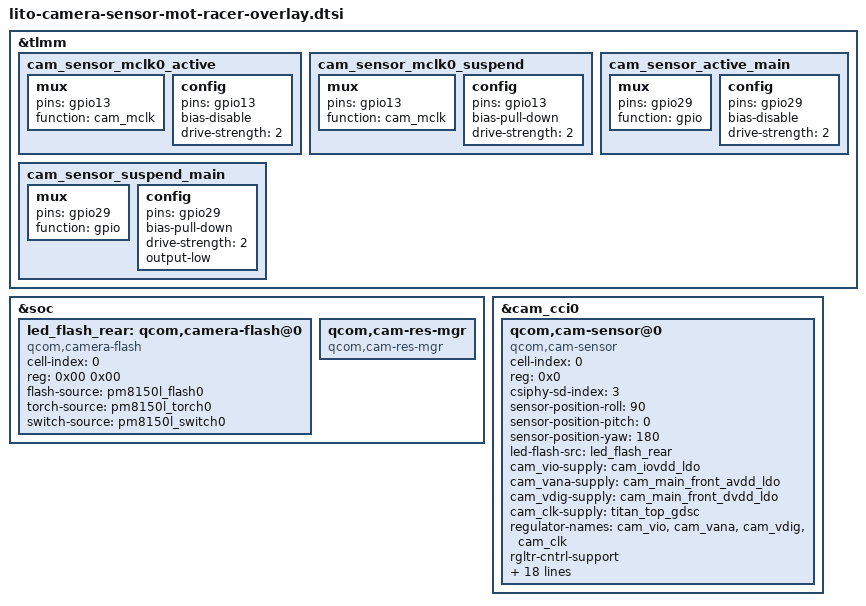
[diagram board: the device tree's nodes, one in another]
#include <dt-bindings/clock/qcom,camcc-lito.h>

&tlmm {
	cam_sensor_mclk0_active: cam_sensor_mclk0_active {
		/* MCLK0 */
		mux {
			pins = "gpio13";
			function = "cam_mclk";
		};

		config {
			pins = "gpio13";
			bias-disable; /* No PULL */
			drive-strength = <2>; /* 2 MA */
		};
	};

	cam_sensor_mclk0_suspend: cam_sensor_mclk0_suspend {
		/* MCLK0 */
		mux {
			pins = "gpio13";
			function = "cam_mclk";
		};

		config {
			pins = "gpio13";
			bias-pull-down; /* PULL DOWN */
			drive-strength = <2>; /* 2 MA */
		};
	};

	cam_sensor_active_main: cam_sensor_active_main {
		/* RESET */
		mux {
			pins = "gpio29";
			function = "gpio";
		};

		config {
			pins = "gpio29";
			bias-disable; /* No PULL */
			drive-strength = <2>; /* 2 MA */
		};
	};

	cam_sensor_suspend_main: cam_sensor_suspend_main {
		/* RESET */
		mux {
			pins = "gpio29";
			function = "gpio";
		};

		config {
			pins = "gpio29";
			bias-pull-down; /* PULL DOWN */
			drive-strength = <2>; /* 2 MA */
			output-low;
		};
	};
};

&soc {
	led_flash_rear: qcom,camera-flash@0 {
		cell-index = <0>;
		reg = <0x00 0x00>;
		compatible = "qcom,camera-flash";
		flash-source = <&pm8150l_flash0>;
		torch-source = <&pm8150l_torch0>;
		switch-source = <&pm8150l_switch0>;
	};

	qcom,cam-res-mgr {
		compatible = "qcom,cam-res-mgr";
		status = "ok";
	};
};

&cam_cci0 {
	qcom,cam-sensor@0 {
		cell-index = <0>;
		compatible = "qcom,cam-sensor";
		reg = <0x0>;
		csiphy-sd-index = <3>;
		sensor-position-roll = <90>;
		sensor-position-pitch = <0>;
		sensor-position-yaw = <180>;
		led-flash-src = <&led_flash_rear>;
		cam_vio-supply = <&cam_iovdd_ldo>;
		cam_vana-supply = <&cam_main_front_avdd_ldo>;
		cam_vdig-supply = <&cam_main_front_dvdd_ldo>;
		cam_clk-supply = <&titan_top_gdsc>;
		regulator-names = "cam_vio", "cam_vana", "cam_vdig",
			"cam_clk";
		rgltr-cntrl-support;
		rgltr-min-voltage = <1800000 2800000 1050000 0>;
		rgltr-max-voltage = <1800000 2800000 1050000 0>;
		rgltr-load-current = <0 80000 105000 0>;
		gpio-no-mux = <0>;
		pinctrl-names = "cam_default", "cam_suspend";
		pinctrl-0 = <&cam_sensor_mclk0_active
				&cam_sensor_active_main>;
		pinctrl-1 = <&cam_sensor_mclk0_suspend
				&cam_sensor_suspend_main>;
		gpios = <&tlmm 13 0>,
			<&tlmm 29 0>;
		gpio-reset = <1>;
		gpio-req-tbl-num = <0 1>;
		gpio-req-tbl-flags = <1 0>;
		gpio-req-tbl-label = "CAMIF_MCLK0",
					"CAM_RESET0";
		cci-device = <0>;
		cci-master = <0>;
		status = "ok";
		clocks = <&camcc CAM_CC_MCLK0_CLK>;
		clock-names = "cam_clk";
		clock-cntl-level = "turbo";
		clock-rates = <24000000>;
	};
};

